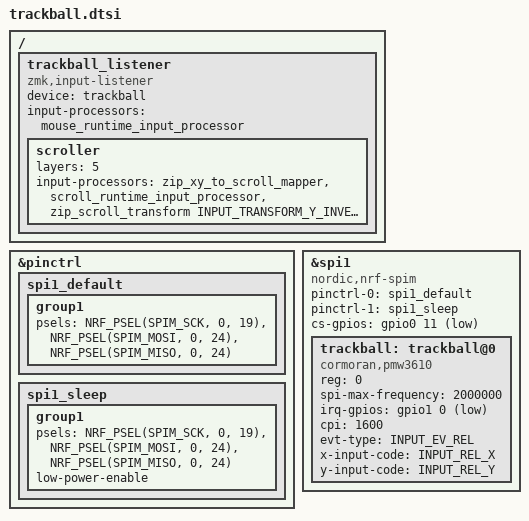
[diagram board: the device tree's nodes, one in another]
#include <zephyr/dt-bindings/input/input-event-codes.h>
#include <dt-bindings/zmk/input_transform.h>
#include <input/processors.dtsi>
#include <input/processors/runtime-input-processor.dtsi>

&pinctrl {
    spi1_default: spi1_default {
        group1 {
            psels = <NRF_PSEL(SPIM_SCK, 0, 19)>,
                <NRF_PSEL(SPIM_MOSI, 0, 24)>,
                <NRF_PSEL(SPIM_MISO, 0, 24)>;
        };
    };

    spi1_sleep: spi1_sleep {
        group1 {
            psels = <NRF_PSEL(SPIM_SCK, 0, 19)>,
                <NRF_PSEL(SPIM_MOSI, 0, 24)>,
                <NRF_PSEL(SPIM_MISO, 0, 24)>;
            low-power-enable;
        };
    };
};

&spi1 {
    status = "okay";
    compatible = "nordic,nrf-spim";
    pinctrl-0 = <&spi1_default>;
    pinctrl-1 = <&spi1_sleep>;
    pinctrl-names = "default", "sleep";
    cs-gpios = <&gpio0 11 GPIO_ACTIVE_LOW>;

    trackball: trackball@0 {
        status = "okay";
        compatible = "cormoran,pmw3610";
        reg = <0>;
        spi-max-frequency = <2000000>;
        irq-gpios = <&gpio1 0 (GPIO_ACTIVE_LOW | GPIO_PULL_UP)>;
        cpi = <1600>;
        evt-type = <INPUT_EV_REL>;
        x-input-code = <INPUT_REL_X>;
        y-input-code = <INPUT_REL_Y>;
    };
};

/ {
    trackball_listener {
        status = "okay";
        compatible = "zmk,input-listener";
        device = <&trackball>;
        input-processors = <&mouse_runtime_input_processor>;

        scroller {
            layers = <5>;
            input-processors =
                <&zip_xy_to_scroll_mapper &scroll_runtime_input_processor>,
                <&zip_scroll_transform INPUT_TRANSFORM_Y_INVERT>;
        };
    };
};
